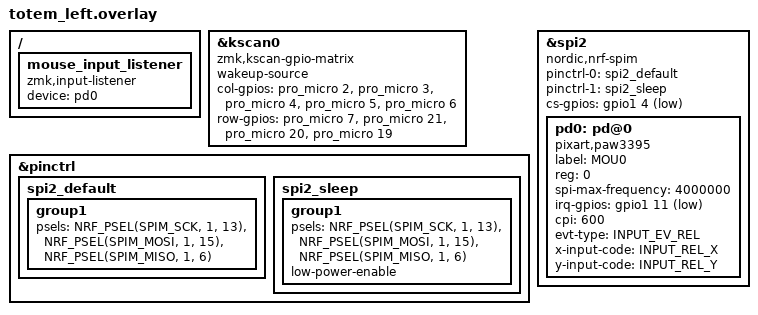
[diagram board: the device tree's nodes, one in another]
/*
 * Copyright (c) 2022 The ZMK Contributors
 *
 * SPDX-License-Identifier: MIT
 */

 #include "totem.dtsi"

 &kscan0 {
    compatible = "zmk,kscan-gpio-matrix";
    wakeup-source;

	col-gpios
		= <&pro_micro 2 GPIO_ACTIVE_HIGH>
		, <&pro_micro 3 GPIO_ACTIVE_HIGH>
		, <&pro_micro 4 GPIO_ACTIVE_HIGH>
		, <&pro_micro 5 GPIO_ACTIVE_HIGH>
		, <&pro_micro 6 GPIO_ACTIVE_HIGH>
		;

    row-gpios
        = <&pro_micro 7 (GPIO_ACTIVE_HIGH | GPIO_PULL_DOWN)>
        , <&pro_micro 21 (GPIO_ACTIVE_HIGH | GPIO_PULL_DOWN)>
        , <&pro_micro 20 (GPIO_ACTIVE_HIGH | GPIO_PULL_DOWN)>
        , <&pro_micro 19 (GPIO_ACTIVE_HIGH | GPIO_PULL_DOWN)>
        ;
 };

 &pinctrl {
	spi2_default: spi2_default {
		group1 {
			psels = <NRF_PSEL(SPIM_SCK, 1, 13)>,
			<NRF_PSEL(SPIM_MOSI, 1, 15)>,
			<NRF_PSEL(SPIM_MISO, 1, 6)>;
		};
	};
	spi2_sleep: spi2_sleep {
		group1 {
			psels = <NRF_PSEL(SPIM_SCK, 1, 13)>,
			<NRF_PSEL(SPIM_MOSI, 1, 15)>,
			<NRF_PSEL(SPIM_MISO, 1, 6)>;
			low-power-enable;
		};
	};
};

#include <zephyr/dt-bindings/input/input-event-codes.h>

&spi2 {
	compatible = "nordic,nrf-spim";
  status = "okay";
	pinctrl-0 = <&spi2_default>;
	pinctrl-1 = <&spi2_sleep>;
	pinctrl-names = "default", "sleep";
	cs-gpios = <&gpio1 4 GPIO_ACTIVE_LOW>;

	pd0: pd@0 {
		compatible = "pixart,paw3395";
	  status = "okay";
		label = "MOU0";
		reg = <0>;
		spi-max-frequency = <4000000>;

		// paw3395 driver parameters
		irq-gpios = <&gpio1 11 (GPIO_ACTIVE_LOW | GPIO_PULL_UP)>;
		cpi = <600>;
		// swap-xy; /* optional */
		// invert-x; /* optional */
		// invert-y; /* optional */
		evt-type = <INPUT_EV_REL>;
		x-input-code = <INPUT_REL_X>;
		y-input-code = <INPUT_REL_Y>;
	};
};

/ {
  mouse_input_listener {
    compatible = "zmk,input-listener";
    device = <&pd0>;
  };
};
